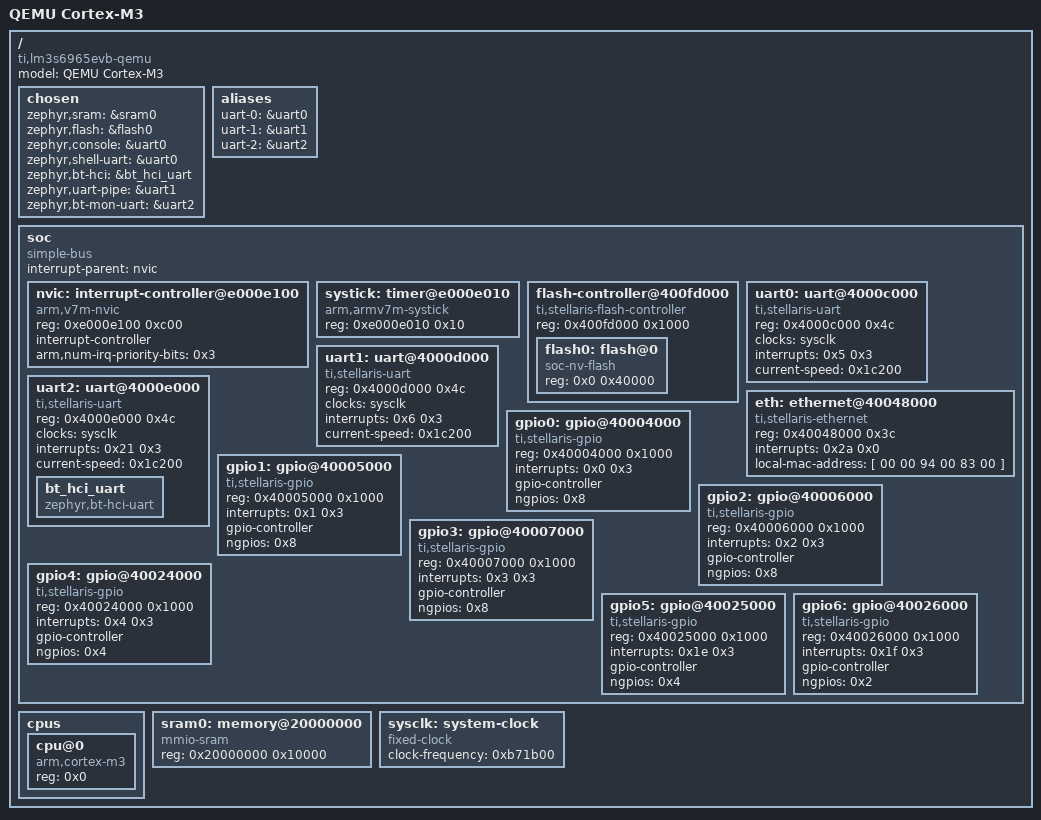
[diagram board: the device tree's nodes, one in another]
/dts-v1/;

/* node '/' defined in deps/zephyr/dts/common/skeleton.dtsi:9 */
/ {
	#address-cells = < 0x1 >;           /* in deps/zephyr/dts/common/skeleton.dtsi:10 */
	#size-cells = < 0x1 >;              /* in deps/zephyr/dts/common/skeleton.dtsi:11 */
	model = "QEMU Cortex-M3";           /* in deps/zephyr/boards/qemu/cortex_m3/qemu_cortex_m3.dts:9 */
	compatible = "ti,lm3s6965evb-qemu",
	             "ti,lm3s6965";         /* in deps/zephyr/boards/qemu/cortex_m3/qemu_cortex_m3.dts:10 */

	/* node '/chosen' defined in deps/zephyr/dts/common/skeleton.dtsi:12 */
	chosen {
		zephyr,sram = &sram0;         /* in deps/zephyr/boards/qemu/cortex_m3/qemu_cortex_m3.dts:19 */
		zephyr,flash = &flash0;       /* in deps/zephyr/boards/qemu/cortex_m3/qemu_cortex_m3.dts:20 */
		zephyr,console = &uart0;      /* in deps/zephyr/boards/qemu/cortex_m3/qemu_cortex_m3.dts:21 */
		zephyr,shell-uart = &uart0;   /* in deps/zephyr/boards/qemu/cortex_m3/qemu_cortex_m3.dts:22 */
		zephyr,bt-hci = &bt_hci_uart; /* in deps/zephyr/boards/qemu/cortex_m3/qemu_cortex_m3.dts:23 */
		zephyr,uart-pipe = &uart1;    /* in deps/zephyr/boards/qemu/cortex_m3/qemu_cortex_m3.dts:24 */
		zephyr,bt-mon-uart = &uart2;  /* in deps/zephyr/boards/qemu/cortex_m3/qemu_cortex_m3.dts:25 */
	};

	/* node '/aliases' defined in deps/zephyr/dts/common/skeleton.dtsi:13 */
	aliases {
		uart-0 = &uart0; /* in deps/zephyr/boards/qemu/cortex_m3/qemu_cortex_m3.dts:13 */
		uart-1 = &uart1; /* in deps/zephyr/boards/qemu/cortex_m3/qemu_cortex_m3.dts:14 */
		uart-2 = &uart2; /* in deps/zephyr/boards/qemu/cortex_m3/qemu_cortex_m3.dts:15 */
	};

	/* node '/soc' defined in deps/zephyr/dts/arm/armv7-m.dtsi:6 */
	soc {
		#address-cells = < 0x1 >;     /* in deps/zephyr/dts/arm/armv7-m.dtsi:7 */
		#size-cells = < 0x1 >;        /* in deps/zephyr/dts/arm/armv7-m.dtsi:8 */
		compatible = "simple-bus";    /* in deps/zephyr/dts/arm/armv7-m.dtsi:9 */
		interrupt-parent = < &nvic >; /* in deps/zephyr/dts/arm/armv7-m.dtsi:10 */
		ranges;                       /* in deps/zephyr/dts/arm/armv7-m.dtsi:11 */

		/* node '/soc/interrupt-controller@e000e100' defined in deps/zephyr/dts/arm/armv7-m.dtsi:13 */
		nvic: interrupt-controller@e000e100 {
			#address-cells = < 0x1 >;            /* in deps/zephyr/dts/arm/armv7-m.dtsi:14 */
			compatible = "arm,v7m-nvic";         /* in deps/zephyr/dts/arm/armv7-m.dtsi:15 */
			reg = < 0xe000e100 0xc00 >;          /* in deps/zephyr/dts/arm/armv7-m.dtsi:16 */
			interrupt-controller;                /* in deps/zephyr/dts/arm/armv7-m.dtsi:17 */
			#interrupt-cells = < 0x2 >;          /* in deps/zephyr/dts/arm/armv7-m.dtsi:18 */
			arm,num-irq-priority-bits = < 0x3 >; /* in deps/zephyr/dts/arm/ti/lm3s6965.dtsi:140 */
			phandle = < 0x1 >;                   /* in deps/zephyr/dts/arm/armv7-m.dtsi:10 */
		};

		/* node '/soc/timer@e000e010' defined in deps/zephyr/dts/arm/armv7-m.dtsi:21 */
		systick: timer@e000e010 {
			compatible = "arm,armv7m-systick"; /* in deps/zephyr/dts/arm/armv7-m.dtsi:22 */
			reg = < 0xe000e010 0x10 >;         /* in deps/zephyr/dts/arm/armv7-m.dtsi:23 */
		};

		/* node '/soc/flash-controller@400fd000' defined in deps/zephyr/dts/arm/ti/lm3s6965.dtsi:30 */
		flash-controller@400fd000 {
			compatible = "ti,stellaris-flash-controller"; /* in deps/zephyr/dts/arm/ti/lm3s6965.dtsi:31 */
			reg = < 0x400fd000 0x1000 >;                  /* in deps/zephyr/dts/arm/ti/lm3s6965.dtsi:32 */
			#address-cells = < 0x1 >;                     /* in deps/zephyr/dts/arm/ti/lm3s6965.dtsi:33 */
			#size-cells = < 0x1 >;                        /* in deps/zephyr/dts/arm/ti/lm3s6965.dtsi:34 */

			/* node '/soc/flash-controller@400fd000/flash@0' defined in deps/zephyr/dts/arm/ti/lm3s6965.dtsi:36 */
			flash0: flash@0 {
				compatible = "soc-nv-flash"; /* in deps/zephyr/dts/arm/ti/lm3s6965.dtsi:37 */
				reg = < 0x0 0x40000 >;       /* in deps/zephyr/dts/arm/ti/lm3s6965.dtsi:38 */
			};
		};

		/* node '/soc/uart@4000c000' defined in deps/zephyr/dts/arm/ti/lm3s6965.dtsi:42 */
		uart0: uart@4000c000 {
			compatible = "ti,stellaris-uart"; /* in deps/zephyr/dts/arm/ti/lm3s6965.dtsi:43 */
			reg = < 0x4000c000 0x4c >;        /* in deps/zephyr/dts/arm/ti/lm3s6965.dtsi:44 */
			clocks = < &sysclk >;             /* in deps/zephyr/dts/arm/ti/lm3s6965.dtsi:45 */
			interrupts = < 0x5 0x3 >;         /* in deps/zephyr/dts/arm/ti/lm3s6965.dtsi:46 */
			status = "okay";                  /* in deps/zephyr/boards/qemu/cortex_m3/qemu_cortex_m3.dts:30 */
			current-speed = < 0x1c200 >;      /* in deps/zephyr/boards/qemu/cortex_m3/qemu_cortex_m3.dts:31 */
		};

		/* node '/soc/uart@4000d000' defined in deps/zephyr/dts/arm/ti/lm3s6965.dtsi:50 */
		uart1: uart@4000d000 {
			compatible = "ti,stellaris-uart"; /* in deps/zephyr/dts/arm/ti/lm3s6965.dtsi:51 */
			reg = < 0x4000d000 0x4c >;        /* in deps/zephyr/dts/arm/ti/lm3s6965.dtsi:52 */
			clocks = < &sysclk >;             /* in deps/zephyr/dts/arm/ti/lm3s6965.dtsi:53 */
			interrupts = < 0x6 0x3 >;         /* in deps/zephyr/dts/arm/ti/lm3s6965.dtsi:54 */
			status = "okay";                  /* in deps/zephyr/boards/qemu/cortex_m3/qemu_cortex_m3.dts:35 */
			current-speed = < 0x1c200 >;      /* in deps/zephyr/boards/qemu/cortex_m3/qemu_cortex_m3.dts:36 */
		};

		/* node '/soc/uart@4000e000' defined in deps/zephyr/dts/arm/ti/lm3s6965.dtsi:58 */
		uart2: uart@4000e000 {
			compatible = "ti,stellaris-uart"; /* in deps/zephyr/dts/arm/ti/lm3s6965.dtsi:59 */
			reg = < 0x4000e000 0x4c >;        /* in deps/zephyr/dts/arm/ti/lm3s6965.dtsi:60 */
			clocks = < &sysclk >;             /* in deps/zephyr/dts/arm/ti/lm3s6965.dtsi:61 */
			interrupts = < 0x21 0x3 >;        /* in deps/zephyr/dts/arm/ti/lm3s6965.dtsi:62 */
			status = "okay";                  /* in deps/zephyr/boards/qemu/cortex_m3/qemu_cortex_m3.dts:40 */
			current-speed = < 0x1c200 >;      /* in deps/zephyr/boards/qemu/cortex_m3/qemu_cortex_m3.dts:41 */

			/* node '/soc/uart@4000e000/bt_hci_uart' defined in deps/zephyr/boards/qemu/cortex_m3/qemu_cortex_m3.dts:43 */
			bt_hci_uart: bt_hci_uart {
				compatible = "zephyr,bt-hci-uart"; /* in deps/zephyr/boards/qemu/cortex_m3/qemu_cortex_m3.dts:44 */
				status = "okay";                   /* in deps/zephyr/boards/qemu/cortex_m3/qemu_cortex_m3.dts:45 */
			};
		};

		/* node '/soc/ethernet@40048000' defined in deps/zephyr/dts/arm/ti/lm3s6965.dtsi:66 */
		eth: ethernet@40048000 {
			compatible = "ti,stellaris-ethernet";      /* in deps/zephyr/dts/arm/ti/lm3s6965.dtsi:67 */
			reg = < 0x40048000 0x3c >;                 /* in deps/zephyr/dts/arm/ti/lm3s6965.dtsi:68 */
			interrupts = < 0x2a 0x0 >;                 /* in deps/zephyr/dts/arm/ti/lm3s6965.dtsi:69 */
			local-mac-address = [ 00 00 94 00 83 00 ]; /* in deps/zephyr/dts/arm/ti/lm3s6965.dtsi:71 */
			status = "okay";                           /* in deps/zephyr/boards/qemu/cortex_m3/qemu_cortex_m3.dts:50 */
		};

		/* node '/soc/gpio@40004000' defined in deps/zephyr/dts/arm/ti/lm3s6965.dtsi:74 */
		gpio0: gpio@40004000 {
			compatible = "ti,stellaris-gpio"; /* in deps/zephyr/dts/arm/ti/lm3s6965.dtsi:75 */
			reg = < 0x40004000 0x1000 >;      /* in deps/zephyr/dts/arm/ti/lm3s6965.dtsi:76 */
			interrupts = < 0x0 0x3 >;         /* in deps/zephyr/dts/arm/ti/lm3s6965.dtsi:77 */
			gpio-controller;                  /* in deps/zephyr/dts/arm/ti/lm3s6965.dtsi:78 */
			#gpio-cells = < 0x2 >;            /* in deps/zephyr/dts/arm/ti/lm3s6965.dtsi:79 */
			ngpios = < 0x8 >;                 /* in deps/zephyr/dts/arm/ti/lm3s6965.dtsi:80 */
			status = "okay";                  /* in deps/zephyr/boards/qemu/cortex_m3/qemu_cortex_m3.dts:54 */
		};

		/* node '/soc/gpio@40005000' defined in deps/zephyr/dts/arm/ti/lm3s6965.dtsi:83 */
		gpio1: gpio@40005000 {
			compatible = "ti,stellaris-gpio"; /* in deps/zephyr/dts/arm/ti/lm3s6965.dtsi:84 */
			reg = < 0x40005000 0x1000 >;      /* in deps/zephyr/dts/arm/ti/lm3s6965.dtsi:85 */
			interrupts = < 0x1 0x3 >;         /* in deps/zephyr/dts/arm/ti/lm3s6965.dtsi:86 */
			gpio-controller;                  /* in deps/zephyr/dts/arm/ti/lm3s6965.dtsi:87 */
			#gpio-cells = < 0x2 >;            /* in deps/zephyr/dts/arm/ti/lm3s6965.dtsi:88 */
			ngpios = < 0x8 >;                 /* in deps/zephyr/dts/arm/ti/lm3s6965.dtsi:89 */
			status = "okay";                  /* in deps/zephyr/boards/qemu/cortex_m3/qemu_cortex_m3.dts:58 */
		};

		/* node '/soc/gpio@40006000' defined in deps/zephyr/dts/arm/ti/lm3s6965.dtsi:92 */
		gpio2: gpio@40006000 {
			compatible = "ti,stellaris-gpio"; /* in deps/zephyr/dts/arm/ti/lm3s6965.dtsi:93 */
			reg = < 0x40006000 0x1000 >;      /* in deps/zephyr/dts/arm/ti/lm3s6965.dtsi:94 */
			interrupts = < 0x2 0x3 >;         /* in deps/zephyr/dts/arm/ti/lm3s6965.dtsi:95 */
			gpio-controller;                  /* in deps/zephyr/dts/arm/ti/lm3s6965.dtsi:96 */
			#gpio-cells = < 0x2 >;            /* in deps/zephyr/dts/arm/ti/lm3s6965.dtsi:97 */
			ngpios = < 0x8 >;                 /* in deps/zephyr/dts/arm/ti/lm3s6965.dtsi:98 */
			status = "okay";                  /* in deps/zephyr/boards/qemu/cortex_m3/qemu_cortex_m3.dts:62 */
		};

		/* node '/soc/gpio@40007000' defined in deps/zephyr/dts/arm/ti/lm3s6965.dtsi:101 */
		gpio3: gpio@40007000 {
			compatible = "ti,stellaris-gpio"; /* in deps/zephyr/dts/arm/ti/lm3s6965.dtsi:102 */
			reg = < 0x40007000 0x1000 >;      /* in deps/zephyr/dts/arm/ti/lm3s6965.dtsi:103 */
			interrupts = < 0x3 0x3 >;         /* in deps/zephyr/dts/arm/ti/lm3s6965.dtsi:104 */
			gpio-controller;                  /* in deps/zephyr/dts/arm/ti/lm3s6965.dtsi:105 */
			#gpio-cells = < 0x2 >;            /* in deps/zephyr/dts/arm/ti/lm3s6965.dtsi:106 */
			ngpios = < 0x8 >;                 /* in deps/zephyr/dts/arm/ti/lm3s6965.dtsi:107 */
			status = "okay";                  /* in deps/zephyr/boards/qemu/cortex_m3/qemu_cortex_m3.dts:66 */
		};

		/* node '/soc/gpio@40024000' defined in deps/zephyr/dts/arm/ti/lm3s6965.dtsi:110 */
		gpio4: gpio@40024000 {
			compatible = "ti,stellaris-gpio"; /* in deps/zephyr/dts/arm/ti/lm3s6965.dtsi:111 */
			reg = < 0x40024000 0x1000 >;      /* in deps/zephyr/dts/arm/ti/lm3s6965.dtsi:112 */
			interrupts = < 0x4 0x3 >;         /* in deps/zephyr/dts/arm/ti/lm3s6965.dtsi:113 */
			gpio-controller;                  /* in deps/zephyr/dts/arm/ti/lm3s6965.dtsi:114 */
			#gpio-cells = < 0x2 >;            /* in deps/zephyr/dts/arm/ti/lm3s6965.dtsi:115 */
			ngpios = < 0x4 >;                 /* in deps/zephyr/dts/arm/ti/lm3s6965.dtsi:116 */
			status = "okay";                  /* in deps/zephyr/boards/qemu/cortex_m3/qemu_cortex_m3.dts:70 */
		};

		/* node '/soc/gpio@40025000' defined in deps/zephyr/dts/arm/ti/lm3s6965.dtsi:119 */
		gpio5: gpio@40025000 {
			compatible = "ti,stellaris-gpio"; /* in deps/zephyr/dts/arm/ti/lm3s6965.dtsi:120 */
			reg = < 0x40025000 0x1000 >;      /* in deps/zephyr/dts/arm/ti/lm3s6965.dtsi:121 */
			interrupts = < 0x1e 0x3 >;        /* in deps/zephyr/dts/arm/ti/lm3s6965.dtsi:122 */
			gpio-controller;                  /* in deps/zephyr/dts/arm/ti/lm3s6965.dtsi:123 */
			#gpio-cells = < 0x2 >;            /* in deps/zephyr/dts/arm/ti/lm3s6965.dtsi:124 */
			ngpios = < 0x4 >;                 /* in deps/zephyr/dts/arm/ti/lm3s6965.dtsi:125 */
			status = "okay";                  /* in deps/zephyr/boards/qemu/cortex_m3/qemu_cortex_m3.dts:74 */
		};

		/* node '/soc/gpio@40026000' defined in deps/zephyr/dts/arm/ti/lm3s6965.dtsi:128 */
		gpio6: gpio@40026000 {
			compatible = "ti,stellaris-gpio"; /* in deps/zephyr/dts/arm/ti/lm3s6965.dtsi:129 */
			reg = < 0x40026000 0x1000 >;      /* in deps/zephyr/dts/arm/ti/lm3s6965.dtsi:130 */
			interrupts = < 0x1f 0x3 >;        /* in deps/zephyr/dts/arm/ti/lm3s6965.dtsi:131 */
			gpio-controller;                  /* in deps/zephyr/dts/arm/ti/lm3s6965.dtsi:132 */
			#gpio-cells = < 0x2 >;            /* in deps/zephyr/dts/arm/ti/lm3s6965.dtsi:133 */
			ngpios = < 0x2 >;                 /* in deps/zephyr/dts/arm/ti/lm3s6965.dtsi:134 */
			status = "okay";                  /* in deps/zephyr/boards/qemu/cortex_m3/qemu_cortex_m3.dts:78 */
		};
	};

	/* node '/cpus' defined in deps/zephyr/dts/arm/ti/lm3s6965.dtsi:6 */
	cpus {
		#address-cells = < 0x1 >; /* in deps/zephyr/dts/arm/ti/lm3s6965.dtsi:7 */
		#size-cells = < 0x0 >;    /* in deps/zephyr/dts/arm/ti/lm3s6965.dtsi:8 */

		/* node '/cpus/cpu@0' defined in deps/zephyr/dts/arm/ti/lm3s6965.dtsi:10 */
		cpu@0 {
			device_type = "cpu";          /* in deps/zephyr/dts/arm/ti/lm3s6965.dtsi:11 */
			compatible = "arm,cortex-m3"; /* in deps/zephyr/dts/arm/ti/lm3s6965.dtsi:12 */
			reg = < 0x0 >;                /* in deps/zephyr/dts/arm/ti/lm3s6965.dtsi:13 */
		};
	};

	/* node '/memory@20000000' defined in deps/zephyr/dts/arm/ti/lm3s6965.dtsi:17 */
	sram0: memory@20000000 {
		compatible = "mmio-sram";     /* in deps/zephyr/dts/arm/ti/lm3s6965.dtsi:18 */
		reg = < 0x20000000 0x10000 >; /* in deps/zephyr/dts/arm/ti/lm3s6965.dtsi:19 */
	};

	/* node '/system-clock' defined in deps/zephyr/dts/arm/ti/lm3s6965.dtsi:22 */
	sysclk: system-clock {
		compatible = "fixed-clock";     /* in deps/zephyr/dts/arm/ti/lm3s6965.dtsi:23 */
		clock-frequency = < 0xb71b00 >; /* in deps/zephyr/dts/arm/ti/lm3s6965.dtsi:24 */
		#clock-cells = < 0x0 >;         /* in deps/zephyr/dts/arm/ti/lm3s6965.dtsi:25 */
		phandle = < 0x2 >;              /* in deps/zephyr/dts/arm/ti/lm3s6965.dtsi:45 */
	};
};
